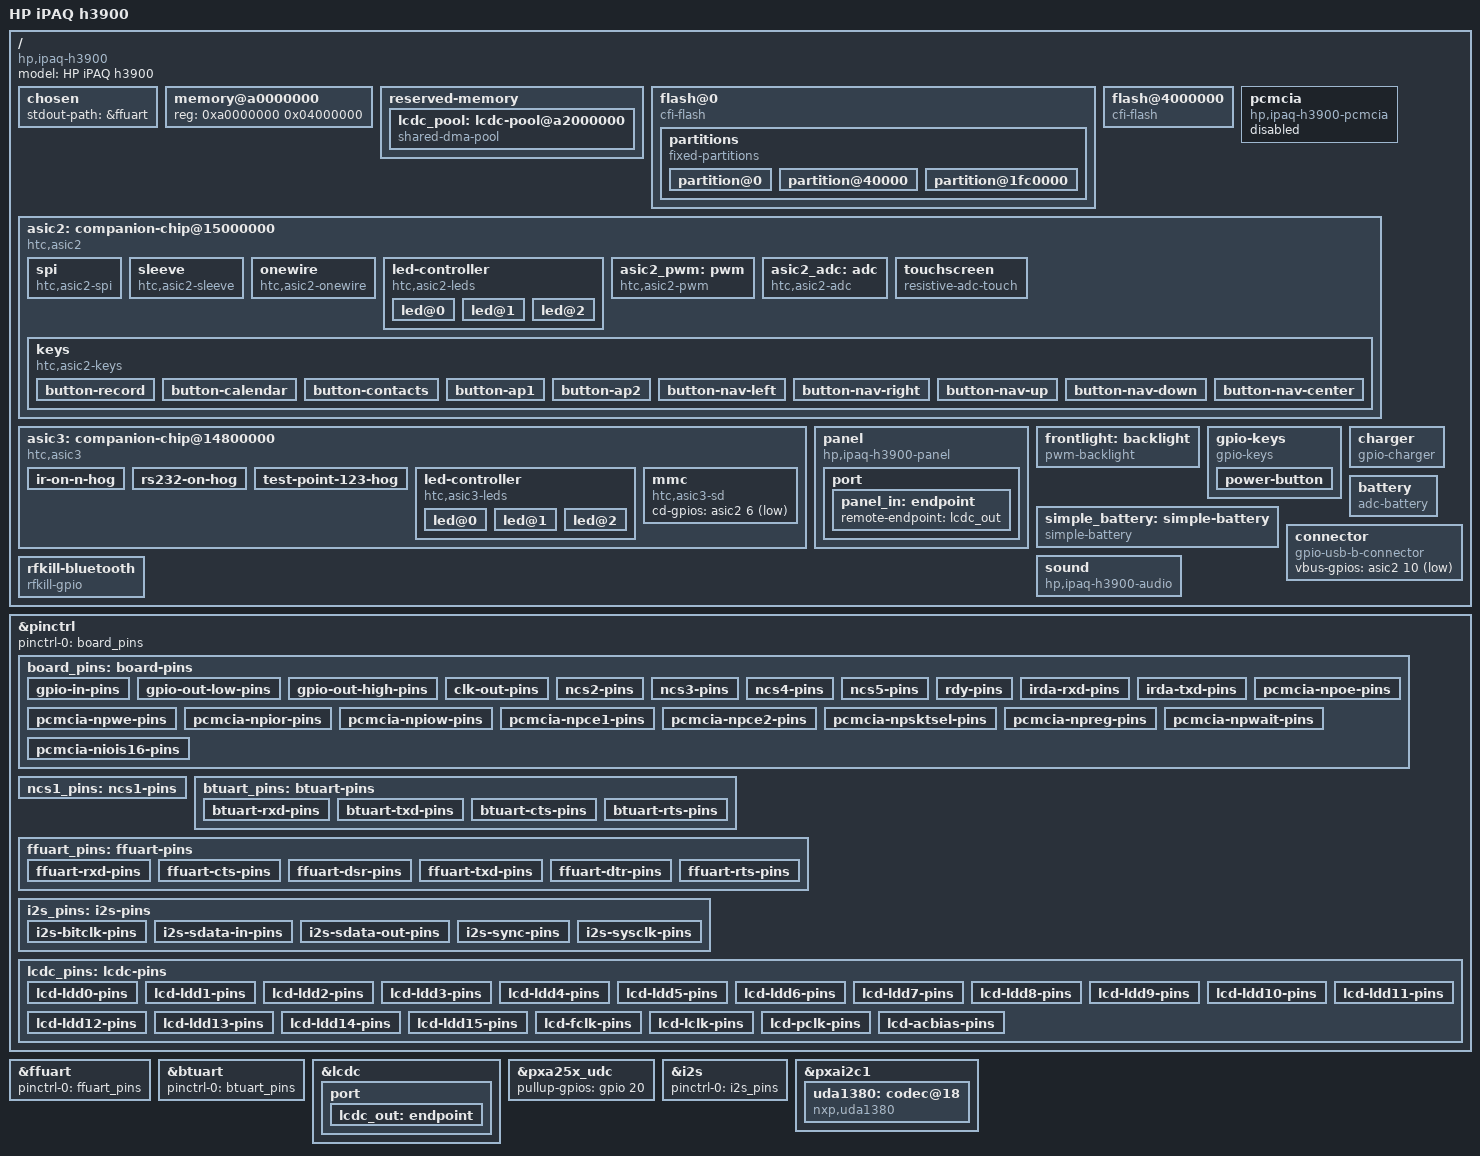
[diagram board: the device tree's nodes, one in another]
// SPDX-License-Identifier: GPL-2.0-only
/*
 * Device tree for the HP/Compaq iPAQ h39xx handheld family (h3950, h3955,
 * h3970 and h3975: one board design, differing in flash size and in
 * whether Bluetooth and the consumer IR are fitted).
 *
 * Named pxa250-* like the other iPAQ boards: the board is a 400 MHz
 * PXA250 and "marvell,pxa250" is the compatible the generic PXA25x
 * devicetree machine matches.
 *
 * The memory node is a 64 MiB placeholder. The boot loader is ATAGS-only,
 * so the board boots from an appended DTB with ARM_ATAG_DTB_COMPAT, which
 * lets the loader's ATAG_MEM replace the reg property
 * (arch/arm/boot/compressed/atags_to_fdt.c).
 *
 * pxa25x.dtsi has no static memory controller node or chip-select
 * ranges, so the devices on the static chip selects are described at
 * their raw physical addresses. The nCS_5 timing is set up from
 * arch/arm/mach-pxa/h3900.c.
 *
 * Copyright (C) 2026 Koen Kooi
 */

/dts-v1/;

#include <dt-bindings/clock/htc,asic2.h>
#include <dt-bindings/gpio/gpio.h>
#include <dt-bindings/input/input.h>
#include <dt-bindings/interrupt-controller/irq.h>
#include <dt-bindings/leds/common.h>

#include "pxa25x.dtsi"

/ {
	model = "HP iPAQ h3900";
	compatible = "hp,ipaq-h3900", "marvell,pxa250";

	chosen {
		stdout-path = &ffuart;
	};

	memory@a0000000 {
		device_type = "memory";
		reg = <0xa0000000 0x04000000>; /* 64 MiB, ATAG_MEM overrides */
	};

	reserved-memory {
		#address-cells = <1>;
		#size-cells = <1>;
		ranges;

		/*
		 * Scanout buffers for the LCD controller. A buffer is a single
		 * order-6 allocation, which fails on this swapping 64 MiB
		 * board, so the buffers come from a reusable CMA region that
		 * movable pages may borrow while it is idle.
		 *
		 * ARM remaps a CMA region in whole 2 MiB page-middle-directory
		 * entries and clears both 1 MiB halves of each one, so the
		 * region has to be 2 MiB aligned and sized: a 1 MiB region left
		 * the next MiB unmapped and the first access to it was a
		 * kernel paging fault. 2 MiB holds twelve 320x240 RGB565
		 * buffers with CMA_ALIGNMENT set to 2.
		 */
		lcdc_pool: lcdc-pool@a2000000 {
			compatible = "shared-dma-pool";
			reusable;
			reg = <0xa2000000 0x00200000>;
		};
	};

	/*
	 * NOR flash on nCS_0: two Intel 28F128J3A (16 MiB, 16 bit each) in a
	 * 2x16 interleave, one 32 MiB CFI window with a 32 bit bus. The
	 * window is 32 MiB on every model; the extra 16 MiB of the 48 MiB
	 * models is the second device on nCS_1 below.
	 */
	flash@0 {
		compatible = "cfi-flash";
		reg = <0x00000000 0x02000000>;
		bank-width = <4>;

		/*
		 * Program and erase supply enable, FLASH_VPEN, active high.
		 * Without it the chip reports "bad VPP" and refuses every
		 * erase and write.
		 */
		vpp-gpios = <&gpio 16 GPIO_ACTIVE_HIGH>;

		#address-cells = <1>;
		#size-cells = <1>;

		/*
		 * A fixed-partitions node because cmdlinepart matches its
		 * mtd_id against the device name, which registers as
		 * "0.flash" and never matches the loader's "ipaq".
		 */
		partitions {
			compatible = "fixed-partitions";
			#address-cells = <1>;
			#size-cells = <1>;

			partition@0 {
				label = "bootldr";
				reg = <0x00000000 0x00040000>;
				read-only;
			};

			partition@40000 {
				label = "root";
				reg = <0x00040000 0x01f80000>;
			};

			partition@1fc0000 {
				label = "asset";
				reg = <0x01fc0000 0x00040000>;
			};
		};
	};

	/*
	 * Second flash device on nCS_1, fitted on the 48 MiB models. It is
	 * a node of its own, not a second reg entry of flash@0, because
	 * physmap fails the whole device when one window does not probe and
	 * units without it must keep their first bank. It has no partitions
	 * and no Vpp line (flash@0 owns it), so it registers as one
	 * read-only mtd device. Its chip select pad is muxed by its own pin
	 * state, so the probe waits for the pin controller.
	 */
	flash@4000000 {
		compatible = "cfi-flash";
		reg = <0x04000000 0x01000000>;
		bank-width = <4>;
		pinctrl-0 = <&ncs1_pins>;
		pinctrl-names = "default";
	};

	/*
	 * The two CompactFlash sockets of an expansion pack, on the PXA's own
	 * PC Card interface. Card detect and the card interrupt are PXA GPIOs
	 * 3, 7 (socket 0) and 12, 13 (socket 1); the reset of the card in
	 * socket 0 is bit 8 of the ASIC2 GPIO bank, the per-card line next to
	 * the whole-pack reset of the sleeve node. The node is disabled
	 * because the socket driver looks it up and assigns it to the socket
	 * device it registers once a pack has been detected.
	 */
	pcmcia {
		compatible = "hp,ipaq-h3900-pcmcia";
		status = "disabled";

		detect-gpios = <&gpio 3 GPIO_ACTIVE_LOW>;
		ready-gpios = <&gpio 7 GPIO_ACTIVE_HIGH>;
		detect1-gpios = <&gpio 12 GPIO_ACTIVE_LOW>;
		ready1-gpios = <&gpio 13 GPIO_ACTIVE_HIGH>;
		reset-gpios = <&asic2 8 GPIO_ACTIVE_HIGH>;
	};

	/*
	 * ASIC2 companion chip on nCS_5, 0x15000000, interrupting the SoC on
	 * GPIO10 (rising edge), one of the pads that can wake a PXA25x.
	 * interrupt-parent is spelled out because the root's is the SoC
	 * interrupt controller, not the GPIO block; the probe is deferred
	 * until the GPIO irqdomain exists.
	 *
	 * nCS_5 has no bus error timeout, so an access before its
	 * variable-latency I/O timing is programmed hangs the core. h3900.c
	 * writes MSC2 from an arch_initcall and the built-in driver binds at
	 * device_initcall, which keeps the order.
	 *
	 * The 16-line gpiochip of the chip serves the SD card detect, the
	 * sleeve connector and the other ASIC2 lines of this board, and the
	 * clock gates are exposed as a provider for the blocks below. The SD
	 * clock tap defaults to 24.576 MHz, which is what this board needs.
	 */
	asic2: companion-chip@15000000 {
		compatible = "htc,asic2";
		reg = <0x15000000 0x2000>;
		interrupt-parent = <&gpio>;
		interrupts = <10 IRQ_TYPE_EDGE_RISING>;
		wakeup-source;

		gpio-controller;
		#gpio-cells = <2>;
		#clock-cells = <1>;

		/*
		 * The byte-at-a-time SPI block. Its register window and
		 * interrupt come from the MFD core; the node exists so that
		 * the sleeve driver can find the controller by its device
		 * node. It has no child nodes: the only two devices on the bus,
		 * the ID EEPROM and the microcontroller of the jacket that is
		 * plugged in, have no fixed identity and are allocated at probe
		 * time.
		 */
		spi {
			compatible = "htc,asic2-spi";
			clocks = <&asic2 ASIC2_CLK_SPI>, <&asic2 ASIC2_CLK_EX1>;
			clock-names = "ref", "ex1";
		};

		/*
		 * Expansion pack ("sleeve" or "option jacket") backend of the
		 * generic iPAQ sleeve bus. Jacket presence is PXA GPIO5
		 * (OPT_IND_N, active low) and the connector's interrupt is
		 * GPIO9 (OPT_INT, rising edge, PXA GPIO interrupts being edge
		 * only). Neither has an alternate function and no other node
		 * uses them; the PC Card interrupt is a different pin. The
		 * jacket's NVRAM supply, main supply and reset are bits 13, 12
		 * and 9 of the ASIC2 GPIO bank.
		 *
		 * Bit 8 (OPT_PCM_RESET, the reset of a single PC Card as
		 * opposed to the whole jacket) is not listed because the
		 * PCMCIA socket driver owns it.
		 *
		 * OPT_BAT_FAULT, GPIO19, is left out: its polarity on this
		 * board is not known, and a wrong flag would report a
		 * permanent battery fault for every jacket without a battery.
		 */
		sleeve {
			compatible = "htc,asic2-sleeve";

			detect-gpios = <&gpio 5 GPIO_ACTIVE_LOW>;
			nvram-gpios = <&asic2 13 GPIO_ACTIVE_HIGH>;
			opt-int-gpios = <&gpio 9 GPIO_ACTIVE_HIGH>;
			power-gpios = <&asic2 12 GPIO_ACTIVE_HIGH>;
			reset-gpios = <&asic2 9 GPIO_ACTIVE_HIGH>;
		};

		/*
		 * The 1-Wire master of the chip, with the tunables the MFD
		 * driver otherwise hardcodes: register stride 2, an active
		 * high interrupt and a 1 ms reset recovery delay.
		 */
		onewire {
			compatible = "htc,asic2-onewire", "dallas,ds1wm";
			dallas,bus-shift = <2>;
			dallas,active-high;
			dallas,reset-recover-delay-ms = <1>;
		};

		/*
		 * The three status LEDs of the board are the ones of this
		 * chip. The colours follow the channel order of the vendor 2.4
		 * kernel, blue, green and yellow; they are not read from the
		 * hardware.
		 *
		 * Channel 1 runs "heartbeat", which is the only liveness
		 * indicator on a board whose console is a serial line that a
		 * wedged CPU stops servicing. Channel 2 follows the MMC host.
		 * Channel 0 has no default trigger.
		 */
		led-controller {
			compatible = "htc,asic2-leds";
			#address-cells = <1>;
			#size-cells = <0>;

			led@0 {
				reg = <0>;
				function = LED_FUNCTION_INDICATOR;
				color = <LED_COLOR_ID_BLUE>;
			};

			led@1 {
				reg = <1>;
				function = LED_FUNCTION_STATUS;
				color = <LED_COLOR_ID_GREEN>;
				linux,default-trigger = "heartbeat";
			};

			led@2 {
				reg = <2>;
				function = LED_FUNCTION_INDICATOR;
				color = <LED_COLOR_ID_AMBER>;
				linux,default-trigger = "mmc0";
			};
		};

		/*
		 * PWM0 drives the frontlight. Divider 7 and period 10 are
		 * what the boot loader programs, stated here so that the board
		 * and not the driver owns them.
		 */
		asic2_pwm: pwm {
			compatible = "htc,asic2-pwm";
			#pwm-cells = <2>;
			clocks = <&asic2 ASIC2_CLK_PWM>, <&asic2 ASIC2_CLK_EX1>;
			clock-names = "ref", "ex1";
			htc,pwm-divider = <7>;
			htc,pwm-period = <10>;
		};

		/*
		 * The ADC of ASIC2, which also serves the resistive
		 * touchscreen. Labelled so that the "touchscreen" node below
		 * reaches it through a real "io-channels" phandle: a
		 * probe-ordering race against this node then becomes an
		 * ordinary deferred probe instead of a permanent failure.
		 */
		asic2_adc: adc {
			compatible = "htc,asic2-adc";
			#io-channel-cells = <1>;
			clocks = <&asic2 ASIC2_CLK_ADC>, <&asic2 ASIC2_CLK_EX1>;
			clock-names = "ref", "ex1";
		};

		/*
		 * The generic resistive-adc-touch driver, consuming the two
		 * touch-plate channels of the ADC block above. The cell values
		 * 3 and 4 are the positions of TP_X0 and TP_Y1 in asic2-adc.c's
		 * channel array: that driver installs no fwnode_xlate, so IIO
		 * indexes the channels directly by this cell value. There is no
		 * "touchscreen-x-plate-ohms" and there are no z1/z2 channels,
		 * since asic2-adc.c synthesises only x and y. The size is the
		 * ADC's real 10 bits.
		 */
		touchscreen {
			compatible = "resistive-adc-touch";
			io-channels = <&asic2_adc 3>, <&asic2_adc 4>;
			io-channel-names = "x", "y";
			touchscreen-size-x = <1024>;
			touchscreen-size-y = <1024>;
		};

		/*
		 * The KPIO keypad. A key is pressed when
		 * (~Data & htc,key-mask) == htc,key-match, which is why each
		 * key has its own child node: the bits of the 5-way pad
		 * combine, and a matrix "linux,keymap" cannot express that.
		 */
		keys {
			compatible = "htc,asic2-keys";

			button-record {
				label = "Record";
				linux,code = <KEY_RECORD>;
				htc,key-mask = <0x001>;
				htc,key-match = <0x001>;
			};

			button-calendar {
				label = "Calendar";
				linux,code = <KEY_CALENDAR>;
				htc,key-mask = <0x040>;
				htc,key-match = <0x040>;
			};

			button-contacts {
				label = "Contacts";
				linux,code = <KEY_ADDRESSBOOK>;
				htc,key-mask = <0x080>;
				htc,key-match = <0x080>;
			};

			button-ap1 {
				label = "Envelope (AP1)";
				linux,code = <KEY_MAIL>;
				htc,key-mask = <0x100>;
				htc,key-match = <0x100>;
			};

			button-ap2 {
				label = "Start (AP2)";
				linux,code = <KEY_HOMEPAGE>;
				htc,key-mask = <0x200>;
				htc,key-match = <0x200>;
			};

			button-nav-left {
				label = "5-way left (AP3)";
				linux,code = <KEY_LEFT>;
				htc,key-mask = <0x400>;
				htc,key-match = <0x400>;
			};

			button-nav-right {
				label = "5-way right (AP4)";
				linux,code = <KEY_RIGHT>;
				htc,key-mask = <0x800>;
				htc,key-match = <0x800>;
			};

			button-nav-up {
				label = "5-way up";
				linux,code = <KEY_UP>;
				htc,key-mask = <0x03e>;
				htc,key-match = <0x032>;
			};

			button-nav-down {
				label = "5-way down";
				linux,code = <KEY_DOWN>;
				htc,key-mask = <0x03e>;
				htc,key-match = <0x02c>;
			};

			button-nav-center {
				label = "5-way centre";
				linux,code = <KEY_ENTER>;
				htc,key-mask = <0x03e>;
				htc,key-match = <0x020>;
			};
		};
	};

	/*
	 * ASIC3 companion chip on nCS_5. The core window is at 0x14800000 and
	 * the SD/MMC block at 0x14000000, both with a 32 bit register stride.
	 *
	 * The board uses no ASIC3 line as an interrupt source, so the node
	 * has no core interrupt and is not an interrupt controller. The only
	 * interrupt is the one of the SD block, which is a SoC GPIO (GPIO4,
	 * MMC_INT_N), not a line of this chip. The chip has no reset line
	 * either.
	 *
	 * The board leaves no line of the four banks floating. Lines that
	 * nothing claims are driven low from probe onwards instead of being
	 * inputs, and the three that start high are hogs below: bank B bit 0
	 * (IR_ON_N), bit 2 (RS232_ON, the supply of the console transceiver)
	 * and bit 15 (TEST_POINT_123).
	 *
	 * The SD card clock comes from ASIC2.
	 */
	asic3: companion-chip@14800000 {
		compatible = "htc,asic3";
		reg = <0x14800000 0x2000>, <0x14000000 0x2000>;
		reg-names = "core", "sd";
		interrupt-parent = <&gpio>;
		interrupts = <4 IRQ_TYPE_EDGE_FALLING>;
		interrupt-names = "sd";
		clocks = <&asic2 ASIC2_CLK_SD>;

		gpio-controller;
		#gpio-cells = <2>;
		htc,gpio-default-output-low;

		ir-on-n-hog {
			gpio-hog;
			gpios = <16 GPIO_ACTIVE_HIGH>;
			output-high;
			line-name = "IR_ON_N";
		};

		rs232-on-hog {
			gpio-hog;
			gpios = <18 GPIO_ACTIVE_HIGH>;
			output-high;
			line-name = "RS232_ON";
		};

		test-point-123-hog {
			gpio-hog;
			gpios = <31 GPIO_ACTIVE_HIGH>;
			output-high;
			line-name = "TEST_POINT_123";
		};

		/*
		 * The LED block of this chip muxes onto GPIO bank C, which the
		 * vendor header does not list as connected on this board, so
		 * the channels are described without colours or triggers: they
		 * keep the block probed and its registers reachable, but the
		 * status LEDs are the ones of ASIC2.
		 */
		led-controller {
			compatible = "htc,asic3-leds";
			#address-cells = <1>;
			#size-cells = <0>;

			led@0 {
				reg = <0>;
				label = "h3900:0";
			};

			led@1 {
				reg = <1>;
				label = "h3900:1";
			};

			led@2 {
				reg = <2>;
				label = "h3900:2";
			};
		};

		/*
		 * Card detect is bit 6 of the GPIO bank of ASIC2, active low:
		 * the bank reads back bit 6 low with a card inserted and high
		 * with it removed.
		 */
		mmc {
			compatible = "htc,asic3-sd";
			cd-gpios = <&asic2 6 GPIO_ACTIVE_LOW>;
		};
	};

	/*
	 * The 320x240 16bpp reflective TFT, scanned by the LCD controller
	 * over GPIO58-77 (LCD_LDD_0..15 plus FCLK, LCLK, PCLK and BIAS, muxed
	 * by the pin state of &lcdc). No part number for the glass is known,
	 * so the panel is named for the machine it is fitted to; its timings
	 * live in the panel driver.
	 *
	 * The five supply rails are ASIC3 bank B outputs, GPIO number 16
	 * plus the bit: B6 is 22, B7 is 23, B5 is 21, B3 is 19 and B1 is
	 * 17. The chip drives all of them low from probe onwards, which keeps
	 * the panel safe before its driver binds.
	 */
	panel {
		compatible = "hp,ipaq-h3900-panel";

		lcd-on-gpios = <&asic3 22 GPIO_ACTIVE_HIGH>;
		lcd-pci-gpios = <&asic3 23 GPIO_ACTIVE_HIGH>;
		lcd-5v-gpios = <&asic3 21 GPIO_ACTIVE_HIGH>;
		lcd-nv-gpios = <&asic3 19 GPIO_ACTIVE_HIGH>;
		lcd-9v-gpios = <&asic3 17 GPIO_ACTIVE_HIGH>;

		/*
		 * The controller scans the glass in 320x240 landscape order
		 * while the handheld is held as a portrait device. The panel
		 * orientation reaches the console as a quarter-turn software
		 * rotation, so no fbcon= argument is needed on the command
		 * line.
		 */
		rotation = <90>;
		backlight = <&frontlight>;

		port {
			panel_in: endpoint {
				remote-endpoint = <&lcdc_out>;
			};
		};
	};

	/*
	 * The panel is reflective and lit from the front, hence the label.
	 * PWM0 of ASIC2 sets the brightness and ASIC3 bank B bit 13, GPIO 29,
	 * powers the light, active high. The handhelds.org 2.6 code sets both
	 * to turn the light on and clears both to turn it off.
	 *
	 * The period in "pwms" is only a unit for the duty arithmetic of
	 * pwm-backlight: the PWM driver always programs the board's fixed
	 * period of 10 and scales the requested duty ratio into that, and no
	 * frequency is known for this divider and period pair.
	 *
	 * The levels are raw duty counts out of that period of 10. Level 0 is
	 * off and the others start at 4, the smallest count that the duty
	 * floor of the PWM driver (about 33%) lets through, so no listed
	 * level is clamped. The default is that floor.
	 */
	frontlight: backlight {
		compatible = "pwm-backlight";
		pwms = <&asic2_pwm 0 100000>;
		enable-gpios = <&asic3 29 GPIO_ACTIVE_HIGH>;
		brightness-levels = <0 4 5 6 7 8 9 10>;
		default-brightness-level = <1>;
	};

	/*
	 * The power button is GPIO0 (POWER_BUTTON_N), active low. It wakes the
	 * system on both edges, the edges gpio-keys requests its interrupt
	 * with.
	 */
	gpio-keys {
		compatible = "gpio-keys";

		power-button {
			label = "Power Button";
			linux,code = <KEY_POWER>;
			gpios = <&gpio 0 GPIO_ACTIVE_LOW>;
			wakeup-source;
		};
	};

	/*
	 * AC adapter presence. GPIO8 is AC_IN_N, a plain SoC GPIO that reads
	 * low while an adapter is connected. It wakes the system on both
	 * edges, the edges gpio-charger requests its interrupt with.
	 *
	 * The charge enable line is bit 4 of ASIC3's GPIO bank B (CH_TIMER),
	 * active high. gpio-charger asserts it at probe and charge_behaviour
	 * switches it from userspace; the time, temperature and full-cell
	 * cutoffs that WinCE applies in software are not in the kernel.
	 */
	charger {
		compatible = "gpio-charger";
		charger-type = "mains";
		gpios = <&gpio 8 GPIO_ACTIVE_LOW>;
		charge-enable-gpios = <&asic3 20 GPIO_ACTIVE_HIGH>;
	};

	/*
	 * adc-battery.yaml requires a "monitored-battery" phandle, but
	 * nothing about the pack (capacity, chemistry, voltage range) is
	 * known, so the node carries only its compatible.
	 */
	simple_battery: simple-battery {
		compatible = "simple-battery";
	};

	/*
	 * Battery voltage through the VS_MBAT channel of the ASIC2 ADC,
	 * channel 2 in the channel array of asic2-adc.c. The channel has no
	 * scale: no count-to-microvolt divider is known for this sense line,
	 * so voltage_now is the raw 10 bit count, not a voltage.
	 */
	battery {
		compatible = "adc-battery";
		io-channels = <&asic2_adc 2>;
		io-channel-names = "voltage";
		monitored-battery = <&simple_battery>;
	};

	/*
	 * VBUS sense for the pxa25x_udc gadget controller, bound by
	 * compatible string: phy-gpio-vbus-usb.c (USB_GPIO_VBUS) matches
	 * "gpio-usb-b-connector" and reads "vbus-gpios", and the UDC finds
	 * the transceiver it registers without a phandle.
	 *
	 * The sense line is bit 10 of the ASIC2 GPIO bank (USB_DETECT_N),
	 * active low. Its interrupt is the ASIC2 one of the same bit, which
	 * the node does not need to list. The connector defers until ASIC2
	 * has probed.
	 */
	connector {
		compatible = "gpio-usb-b-connector", "usb-b-connector";
		vbus-gpios = <&asic2 10 GPIO_ACTIVE_LOW>;
	};

	/*
	 * The audio card of the UDA1380. speaker-gpios is GPIO3_SPK_ON, ASIC3
	 * bank B bit 12 (offset 16 + 12 = 28), an active high amplifier
	 * enable. jack-gpios is ASIC2 GPIO2 bit 7 (EAR_IN_N), which reads low
	 * while a plug is inserted. A GPIO phandle resolves through the
	 * gpiochip of &asic2 like the card detect of the mmc node does. The
	 * only microphone is built in and biased by the codec itself, so
	 * there is no line for it.
	 */
	sound {
		compatible = "hp,ipaq-h3900-audio";

		cpu-dai = <&i2s>;
		audio-codec = <&uda1380>;

		speaker-gpios = <&asic3 28 GPIO_ACTIVE_HIGH>;
		jack-gpios = <&asic2 7 GPIO_ACTIVE_LOW>;
	};

	/*
	 * GPIO3_BT_PWR_ON, ASIC3 bank B bit 11 (offset 27), powers the
	 * Bluetooth module and is the only control line: there is no reset
	 * line and no settle delay. The pin comes up low from
	 * htc,gpio-default-output-low, so the radio starts off.
	 */
	rfkill-bluetooth {
		compatible = "rfkill-gpio";
		label = "bluetooth";
		radio-type = "bluetooth";
		shutdown-gpios = <&asic3 27 GPIO_ACTIVE_HIGH>;
		default-blocked;
	};
};

/*
 * Pin muxing and sleep levels of the PXA pads. A pad with a consumer node
 * gets its state from that node; the pads that the board uses without one
 * (plain GPIOs, chip selects, the PC Card strobes) are set by the default
 * state of the pin controller itself when it probes. The muxing and the
 * sleep levels are those of the vendor 2.4 kernel; GPIO81-84 are not used
 * and stay as the boot loader left them.
 *
 * low-power-disable and low-power-enable select the level an output pad is
 * driven to while the SoC sleeps; a pad without either keeps the sleep
 * level the boot loader programmed. Inputs are not driven in sleep.
 */
&pinctrl {
	pinctrl-names = "default";
	pinctrl-0 = <&board_pins>;

	board_pins: board-pins {
		/*
		 * POWER_BUTTON_N, RTS, PCMCIA_CD0_N, MMC_INT_N, OPT_IND_N,
		 * GPIO6, PCMCIA_IRQ0_N, AC_IN_N, OPT_INT, ASIC2_INT,
		 * PCMCIA_CD1_N, PCMCIA_IRQ1_N, COM_DCD, SD_IRQ, OPT_BAT_FAULT,
		 * GPIO21 and SD_WP_N. GPIO27 is the audio clock tap of ASIC2
		 * and stays an input so that the SoC never drives against it.
		 */
		gpio-in-pins {
			groups = "P0", "P1", "P3", "P4", "P5", "P6", "P7", "P8",
				 "P9", "P10", "P12", "P13", "P14", "P17", "P19",
				 "P21", "P27", "P38";
			function = "gpio_in";
		};

		/*
		 * CIR_RST, FLASH_VPEN, USBP_PULLUP, GPIO22 and the four SSP
		 * pads, used as plain outputs.
		 */
		gpio-out-low-pins {
			groups = "P2", "P16", "P20", "P22", "P23", "P24", "P25",
				 "P26";
			function = "gpio_out";
			low-power-disable;
		};

		/* A plain output on this board, not the FFUART DCD input. */
		gpio-out-high-pins {
			groups = "P36";
			function = "gpio_out";
			low-power-enable;
		};

		clk-out-pins {
			groups = "P11";
			function = "3_6_MHz";
			low-power-disable;
		};

		ncs2-pins {
			groups = "P78";
			function = "nCS<2>";
			low-power-enable;
		};

		ncs3-pins {
			groups = "P79";
			function = "nCS<3>";
			low-power-enable;
		};

		ncs4-pins {
			groups = "P80";
			function = "nCS<4>";
			low-power-enable;
		};

		/* ASIC2 and ASIC3 */
		ncs5-pins {
			groups = "P33";
			function = "nCS[5]";
			low-power-enable;
		};

		rdy-pins {
			groups = "P18";
			function = "RDY";
		};

		irda-rxd-pins {
			groups = "P46";
			function = "ICP_RXD";
		};

		irda-txd-pins {
			groups = "P47";
			function = "ICP_TXD";
			low-power-disable;
		};

		/* The two PC Card sockets of an expansion pack */
		pcmcia-npoe-pins {
			groups = "P48";
			function = "nPOE";
			low-power-enable;
		};

		pcmcia-npwe-pins {
			groups = "P49";
			function = "nPWE";
			low-power-enable;
		};

		pcmcia-npior-pins {
			groups = "P50";
			function = "nPIOR";
			low-power-enable;
		};

		pcmcia-npiow-pins {
			groups = "P51";
			function = "nPIOW";
			low-power-enable;
		};

		pcmcia-npce1-pins {
			groups = "P52";
			function = "nPCE[1]";
			low-power-enable;
		};

		pcmcia-npce2-pins {
			groups = "P53";
			function = "nPCE[2]";
			low-power-enable;
		};

		pcmcia-npsktsel-pins {
			groups = "P54";
			function = "nPSKTSEL";
			low-power-enable;
		};

		pcmcia-npreg-pins {
			groups = "P55";
			function = "nPREG";
			low-power-enable;
		};

		pcmcia-npwait-pins {
			groups = "P56";
			function = "nPWAIT";
		};

		pcmcia-niois16-pins {
			groups = "P57";
			function = "nIOIS16";
		};
	};

	/* The second flash device of the 48 MiB models */
	ncs1_pins: ncs1-pins {
		groups = "P15";
		function = "nCS_1";
		low-power-enable;
	};

	btuart_pins: btuart-pins {
		btuart-rxd-pins {
			groups = "P42";
			function = "BTRXD";
		};

		btuart-txd-pins {
			groups = "P43";
			function = "BTTXD";
			low-power-disable;
		};

		btuart-cts-pins {
			groups = "P44";
			function = "BTCTS";
		};

		btuart-rts-pins {
			groups = "P45";
			function = "BTRTS";
			low-power-disable;
		};
	};

	ffuart_pins: ffuart-pins {
		ffuart-rxd-pins {
			groups = "P34";
			function = "FFRXD";
		};

		ffuart-cts-pins {
			groups = "P35";
			function = "CTS";
		};

		ffuart-dsr-pins {
			groups = "P37";
			function = "DSR";
		};

		ffuart-txd-pins {
			groups = "P39";
			function = "FFTXD";
			low-power-disable;
		};

		ffuart-dtr-pins {
			groups = "P40";
			function = "DTR";
			low-power-enable;
		};

		ffuart-rts-pins {
			groups = "P41";
			function = "RTS";
			low-power-disable;
		};
	};

	/*
	 * The I2S pads. The output pads sleep low so the I2S clocks are
	 * stopped in suspend.
	 */
	i2s_pins: i2s-pins {
		i2s-bitclk-pins {
			groups = "P28";
			function = "I2S_BITCLK_OUT";
			low-power-disable;
		};

		i2s-sdata-in-pins {
			groups = "P29";
			function = "I2S_SDATA_IN";
		};

		i2s-sdata-out-pins {
			groups = "P30";
			function = "I2S_SDATA_OUT";
			low-power-disable;
		};

		i2s-sync-pins {
			groups = "P31";
			function = "I2S_SYNC";
			low-power-disable;
		};

		i2s-sysclk-pins {
			groups = "P32";
			function = "I2S_SYSCLK";
			low-power-disable;
		};
	};

	/* The panel's data and control lines; all sleep low. */
	lcdc_pins: lcdc-pins {
		lcd-ldd0-pins {
			groups = "P58";
			function = "LDD<0>";
			low-power-disable;
		};

		lcd-ldd1-pins {
			groups = "P59";
			function = "LDD<1>";
			low-power-disable;
		};

		lcd-ldd2-pins {
			groups = "P60";
			function = "LDD<2>";
			low-power-disable;
		};

		lcd-ldd3-pins {
			groups = "P61";
			function = "LDD<3>";
			low-power-disable;
		};

		lcd-ldd4-pins {
			groups = "P62";
			function = "LDD<4>";
			low-power-disable;
		};

		lcd-ldd5-pins {
			groups = "P63";
			function = "LDD<5>";
			low-power-disable;
		};

		lcd-ldd6-pins {
			groups = "P64";
			function = "LDD<6>";
			low-power-disable;
		};

		lcd-ldd7-pins {
			groups = "P65";
			function = "LDD<7>";
			low-power-disable;
		};

		lcd-ldd8-pins {
			groups = "P66";
			function = "LDD<8>";
			low-power-disable;
		};

		lcd-ldd9-pins {
			groups = "P67";
			function = "LDD<9>";
			low-power-disable;
		};

		lcd-ldd10-pins {
			groups = "P68";
			function = "LDD<10>";
			low-power-disable;
		};

		lcd-ldd11-pins {
			groups = "P69";
			function = "LDD<11>";
			low-power-disable;
		};

		lcd-ldd12-pins {
			groups = "P70";
			function = "LDD<12>";
			low-power-disable;
		};

		lcd-ldd13-pins {
			groups = "P71";
			function = "LDD<13>";
			low-power-disable;
		};

		lcd-ldd14-pins {
			groups = "P72";
			function = "LDD<14>";
			low-power-disable;
		};

		lcd-ldd15-pins {
			groups = "P73";
			function = "LDD<15>";
			low-power-disable;
		};

		lcd-fclk-pins {
			groups = "P74";
			function = "LCD_FCLK";
			low-power-disable;
		};

		lcd-lclk-pins {
			groups = "P75";
			function = "LCD_LCLK";
			low-power-disable;
		};

		lcd-pclk-pins {
			groups = "P76";
			function = "LCD_PCLK";
			low-power-disable;
		};

		lcd-acbias-pins {
			groups = "P77";
			function = "LCD_ACBIAS";
			low-power-disable;
		};
	};
};

&ffuart {
	pinctrl-0 = <&ffuart_pins>;
	pinctrl-names = "default";

	status = "okay";
};

/*
 * Serial link of the Bluetooth module of the h3970 and h3975; the h3950
 * and h3955 leave the module unpopulated and nothing answers there.
 */
&btuart {
	pinctrl-0 = <&btuart_pins>;
	pinctrl-names = "default";

	status = "okay";
};

/*
 * 16 is the panel's RGB565 data width over LCD_LDD_0..15. The register
 * window, interrupt and clock come from pxa2xx.dtsi.
 */
&lcdc {
	memory-region = <&lcdc_pool>;
	pinctrl-0 = <&lcdc_pins>;
	pinctrl-names = "default";
	status = "okay";

	port {
		lcdc_out: endpoint {
			remote-endpoint = <&panel_in>;
			bus-width = <16>;
		};
	};
};

/*
 * GPIO20 (USBP_PULLUP) switches the D+ pullup, active high. The driver owns
 * it directly rather than through the gpio-vbus transceiver, which only
 * senses VBUS here (see the "connector" node).
 */
&pxa25x_udc {
	pullup-gpios = <&gpio 20 GPIO_ACTIVE_HIGH>;
	status = "okay";
};

/*
 * The I2S block of pxa2xx.dtsi, which the audio card above uses, with its
 * pads muxed by its own pin state.
 */
&i2s {
	pinctrl-0 = <&i2s_pins>;
	pinctrl-names = "default";

	status = "okay";
};

/*
 * UDA1380 audio codec on the plain PXA25x I2C controller, at 0x18. i2c1
 * is the alias of &pxai2c1, which makes the codec component
 * "uda1380-codec.1-0018". reset-gpios is GPIO3_AUD_RESET, ASIC3 bank B
 * bit 10 (offset 26), and power-gpios GPIO3_AUD_PWR_ON, bit 14 (offset
 * 30); both are active high, the codec driver powers the chip with
 * power-gpios and then pulses reset-gpios high and low. dac-clk selects
 * the word-select PLL, which locks to the I2S frame clock the PXA always
 * drives, so the DAC does not depend on GPIO32 (I2S_SYSCLK) reaching the
 * codec's SYSCLK pin. The ADC clock is left at its default. The PLL is
 * powered per stream by the codec driver, so recording and playing at
 * the same time is expected to silence playback.
 */
&pxai2c1 {
	status = "okay";

	uda1380: codec@18 {
		compatible = "nxp,uda1380";
		reg = <0x18>;

		reset-gpios = <&asic3 26 GPIO_ACTIVE_HIGH>;
		power-gpios = <&asic3 30 GPIO_ACTIVE_HIGH>;
		dac-clk = "wspll";

		#sound-dai-cells = <0>;
	};
};
